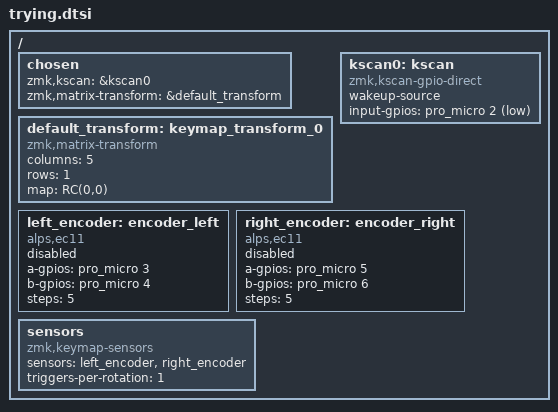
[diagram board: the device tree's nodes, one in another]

#include <dt-bindings/zmk/matrix_transform.h>
/ {
	chosen {
		zmk,kscan = &kscan0;
		zmk,matrix-transform = &default_transform;
	};

	default_transform: keymap_transform_0 {
		compatible = "zmk,matrix-transform";
		columns = <5>;
		rows = <1>;
		map = <
RC(0,0)   
		>;
	};

	kscan0: kscan {
		compatible = "zmk,kscan-gpio-direct";
		wakeup-source;

		input-gpios
			= <&pro_micro 2 (GPIO_ACTIVE_LOW | GPIO_PULL_UP)>
			;
	};
    left_encoder: encoder_left {
        compatible = "alps,ec11";
        a-gpios = <&pro_micro 3 (GPIO_ACTIVE_HIGH | GPIO_PULL_UP)>;
        b-gpios = <&pro_micro 4 (GPIO_ACTIVE_HIGH | GPIO_PULL_UP)>;
        steps = <5>;
        status = "disabled";
    };

    right_encoder: encoder_right {
        compatible = "alps,ec11";
        a-gpios = <&pro_micro 5 (GPIO_ACTIVE_HIGH | GPIO_PULL_UP)>;
        b-gpios = <&pro_micro 6 (GPIO_ACTIVE_HIGH | GPIO_PULL_UP)>;
        steps = <5>;
        status = "disabled";
    };

    sensors: sensors {
        compatible = "zmk,keymap-sensors";
        sensors = <&left_encoder &right_encoder>;
        triggers-per-rotation = <1>;
    };

};
